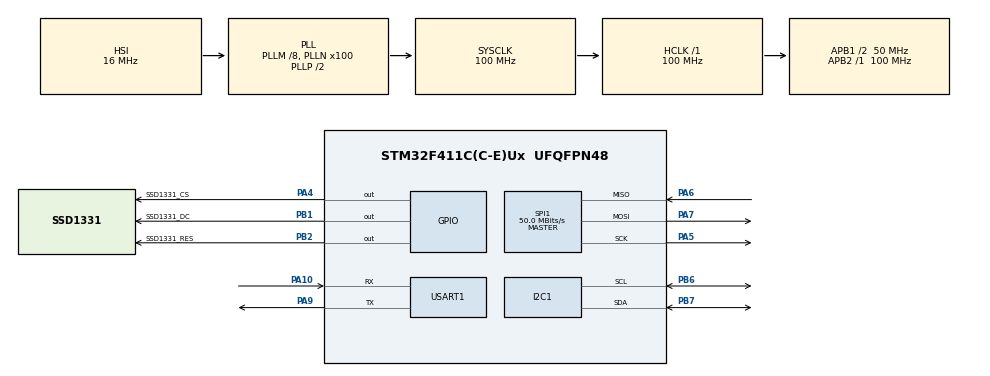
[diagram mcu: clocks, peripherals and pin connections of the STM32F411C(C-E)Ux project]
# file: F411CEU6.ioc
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Dma.Request0=USART1_RX
Dma.USART1_RX.0.Direction=DMA_PERIPH_TO_MEMORY
Dma.USART1_RX.0.FIFOMode=DMA_FIFOMODE_DISABLE
Dma.USART1_RX.0.Instance=DMA2_Stream2
Dma.USART1_RX.0.MemDataAlignment=DMA_MDATAALIGN_BYTE
Dma.USART1_RX.0.MemInc=DMA_MINC_ENABLE
Dma.USART1_RX.0.Mode=DMA_CIRCULAR
Dma.USART1_RX.0.PeriphDataAlignment=DMA_PDATAALIGN_BYTE
Dma.USART1_RX.0.PeriphInc=DMA_PINC_DISABLE
Dma.USART1_RX.0.Priority=DMA_PRIORITY_LOW
FREERTOS.Queues01=uart_tx_queue,4,UART_TX_QUEUE_MSG_t,0,Dynamic,NULL,NULL;display_queue,4,DISPLAY_MSG_t,0,Dynamic,NULL,NULL
FREERTOS.Tasks01=SENSOR_TASK,8,512,SENSOR_TASK_Start,Default,NULL,Dynamic,NULL,NULL;UART_TX_TASK,8,256,UART_TX_TASK_Start,Default,NULL,Dynamic,NULL,NULL;DISPLAY_TASK,40,256,DISPLAY_TASK_Start,Default,NULL,Dynamic,NULL,NULL;UART_RX_TASK,24,512,UART_RX_TASK_Start,Default,NULL,Dynamic,NULL,NULL;FLASH_LOG_TASK,8,256,FLASH_LOG_TASK_Start,Default,NULL,Dynamic,NULL,NULL
Mcu.Family=STM32F4
Mcu.Name=STM32F411C(C-E)Ux
Mcu.Package=UFQFPN48
NVIC.DMA2_Stream2_IRQn=true\:5\:0\:false\:false\:true\:true\:false\:true\:true
NVIC.PriorityGroup=NVIC_PRIORITYGROUP_4
NVIC.RTC_WKUP_IRQn=true\:5\:0\:false\:false\:true\:true\:true\:true\:true
NVIC.USART1_IRQn=true\:5\:0\:false\:false\:true\:true\:true\:true\:true
PA10.Mode=Asynchronous
PA10.Signal=USART1_RX
PA4.GPIO_Label=SSD1331_CS
PA4.GPIO_PuPd=GPIO_PULLUP
PA4.PinState=GPIO_PIN_SET
PA4.Signal=GPIO_Output
PA5.Mode=Full_Duplex_Master
PA5.Signal=SPI1_SCK
PA6.Mode=Full_Duplex_Master
PA6.Signal=SPI1_MISO
PA7.Mode=Full_Duplex_Master
PA7.Signal=SPI1_MOSI
PA9.Mode=Asynchronous
PA9.Signal=USART1_TX
PB1.GPIO_Label=SSD1331_DC
PB1.GPIO_PuPd=GPIO_PULLUP
PB1.PinState=GPIO_PIN_SET
PB1.Signal=GPIO_Output
PB2.GPIO_Label=SSD1331_RES
PB2.GPIO_PuPd=GPIO_PULLUP
PB2.PinState=GPIO_PIN_SET
PB2.Signal=GPIO_Output
PB6.Mode=I2C
PB6.Signal=I2C1_SCL
PB7.Mode=I2C
PB7.Signal=I2C1_SDA
ProjectManager.HeapSize=0x200
ProjectManager.StackSize=0x400
ProjectManager.TargetToolchain=STM32CubeIDE
RCC.48MHZClocksFreq_Value=50000000
RCC.AHBFreq_Value=100000000
RCC.APB1CLKDivider=RCC_HCLK_DIV2
RCC.APB1Freq_Value=50000000
RCC.APB1TimFreq_Value=100000000
RCC.APB2Freq_Value=100000000
RCC.APB2TimFreq_Value=100000000
RCC.CortexFreq_Value=100000000
RCC.HCLKFreq_Value=100000000
RCC.HSE_VALUE=25000000
RCC.HSI_VALUE=16000000
RCC.PLLM=8
RCC.PLLN=100
RCC.RCC_RTC_Clock_Source=RCC_RTCCLKSOURCE_LSI
RCC.RCC_RTC_Clock_SourceVirtual=RCC_RTCCLKSOURCE_LSE
RCC.RCC_RTC_Clock_Source_FROM_HSE=RCC_RTCCLKSOURCE_HSE_DIV25
RCC.SYSCLKFreq_VALUE=100000000
RCC.SYSCLKSource=RCC_SYSCLKSOURCE_PLLCLK
RCC.VCOOutputFreq_Value=200000000
RTC.WakeUpClock=RTC_WAKEUPCLOCK_CK_SPRE_16BITS
RTC.WakeUpCounter=10
SPI1.BaudRatePrescaler=SPI_BAUDRATEPRESCALER_2
SPI1.CalculateBaudRate=50.0 MBits/s
SPI1.Direction=SPI_DIRECTION_2LINES
SPI1.Mode=SPI_MODE_MASTER
SPI1.VirtualType=VM_MASTER
USART1.VirtualMode=VM_ASYNC
VP_FREERTOS_VS_CMSIS_V2.Mode=CMSIS_V2
VP_RTC_VS_RTC_Activate.Mode=RTC_Enabled
VP_RTC_VS_RTC_WakeUp_intern.Mode=WakeUp
board=custom

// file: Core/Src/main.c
/* USER CODE BEGIN Header */
/**
 ******************************************************************************
 * @file           : main.c
 * @brief          : Main program body
 ******************************************************************************
 * @attention
 *
 * Copyright (c) 2026 STMicroelectronics.
 * All rights reserved.
 *
 * This software is licensed under terms that can be found in the LICENSE file
 * in the root directory of this software component.
 * If no LICENSE file comes with this software, it is provided AS-IS.
 *
 ******************************************************************************
 */
/* USER CODE END Header */
#include "main.h"
#include "cmsis_os.h"

/* USER CODE BEGIN Includes */
#include "stdio.h"
#include "string.h"
#include "common.h"
#include "task/display_task.h"
#include "task/sensor_task.h"
#include "task/uart_tx_task.h"
#include "task/uart_rx_task.h"
#include "task/flash_logger_task.h"
/* USER CODE END Includes */

I2C_HandleTypeDef hi2c1;

RTC_HandleTypeDef hrtc;

SPI_HandleTypeDef hspi1;

UART_HandleTypeDef huart1;
DMA_HandleTypeDef hdma_usart1_rx;

/* Definitions for SENSOR_TASK */
osThreadId_t SENSOR_TASKHandle;
const osThreadAttr_t SENSOR_TASK_attributes = {
  .name = "SENSOR_TASK",
  .stack_size = 512 * 4,
  .priority = (osPriority_t) osPriorityLow,
};
/* Definitions for UART_TX_TASK */
osThreadId_t UART_TX_TASKHandle;
const osThreadAttr_t UART_TX_TASK_attributes = {
  .name = "UART_TX_TASK",
  .stack_size = 256 * 4,
  .priority = (osPriority_t) osPriorityLow,
};
/* Definitions for DISPLAY_TASK */
osThreadId_t DISPLAY_TASKHandle;
const osThreadAttr_t DISPLAY_TASK_attributes = {
  .name = "DISPLAY_TASK",
  .stack_size = 256 * 4,
  .priority = (osPriority_t) osPriorityHigh,
};
/* Definitions for UART_RX_TASK */
osThreadId_t UART_RX_TASKHandle;
const osThreadAttr_t UART_RX_TASK_attributes = {
  .name = "UART_RX_TASK",
  .stack_size = 512 * 4,
  .priority = (osPriority_t) osPriorityNormal,
};
/* Definitions for FLASH_LOG_TASK */
osThreadId_t FLASH_LOG_TASKHandle;
const osThreadAttr_t FLASH_LOG_TASK_attributes = {
  .name = "FLASH_LOG_TASK",
  .stack_size = 256 * 4,
  .priority = (osPriority_t) osPriorityLow,
};
/* Definitions for uart_tx_queue */
osMessageQueueId_t uart_tx_queueHandle;
const osMessageQueueAttr_t uart_tx_queue_attributes = {
  .name = "uart_tx_queue"
};
/* Definitions for display_queue */
osMessageQueueId_t display_queueHandle;
const osMessageQueueAttr_t display_queue_attributes = {
  .name = "display_queue"
};

void SystemClock_Config(void);
static void MX_GPIO_Init(void);
static void MX_DMA_Init(void);
static void MX_USART1_UART_Init(void);
static void MX_RTC_Init(void);
static void MX_I2C1_Init(void);
static void MX_SPI1_Init(void);
void SENSOR_TASK_Start(void *argument);
void UART_TX_TASK_Start(void *argument);
void DISPLAY_TASK_Start(void *argument);
void UART_RX_TASK_Start(void *argument);
void FLASH_LOG_TASK_Start(void *argument);

int main(void)
{

  /* MCU Configuration--------------------------------------------------------*/

  /* Reset of all peripherals, Initializes the Flash interface and the Systick. */
  HAL_Init();

  /* Configure the system clock */
  SystemClock_Config();

  /* Initialize all configured peripherals */
  MX_GPIO_Init();
  MX_DMA_Init();
  MX_USART1_UART_Init();
  MX_RTC_Init();
  MX_I2C1_Init();
  MX_SPI1_Init();

  /* Init scheduler */
  osKernelInitialize();

  /* Create the queue(s) */
  /* creation of uart_tx_queue */
  uart_tx_queueHandle = osMessageQueueNew (4, sizeof(UART_TX_QUEUE_MSG_t), &uart_tx_queue_attributes);

  /* creation of display_queue */
  display_queueHandle = osMessageQueueNew (4, sizeof(DISPLAY_MSG_t), &display_queue_attributes);

  /* Create the thread(s) */
  /* creation of SENSOR_TASK */
  SENSOR_TASKHandle = osThreadNew(SENSOR_TASK_Start, NULL, &SENSOR_TASK_attributes);

  /* creation of UART_TX_TASK */
  UART_TX_TASKHandle = osThreadNew(UART_TX_TASK_Start, NULL, &UART_TX_TASK_attributes);

  /* creation of DISPLAY_TASK */
  DISPLAY_TASKHandle = osThreadNew(DISPLAY_TASK_Start, NULL, &DISPLAY_TASK_attributes);

  /* creation of UART_RX_TASK */
  UART_RX_TASKHandle = osThreadNew(UART_RX_TASK_Start, NULL, &UART_RX_TASK_attributes);

  /* creation of FLASH_LOG_TASK */
  FLASH_LOG_TASKHandle = osThreadNew(FLASH_LOG_TASK_Start, NULL, &FLASH_LOG_TASK_attributes);

  /* Start scheduler */
  osKernelStart();

  /* We should never get here as control is now taken by the scheduler */

  /* Infinite loop */
	while (1) {

	}
}

void SystemClock_Config(void)
{
  RCC_OscInitTypeDef RCC_OscInitStruct = {0};
  RCC_ClkInitTypeDef RCC_ClkInitStruct = {0};

  /** Configure the main internal regulator output voltage
  */
  __HAL_RCC_PWR_CLK_ENABLE();
  __HAL_PWR_VOLTAGESCALING_CONFIG(PWR_REGULATOR_VOLTAGE_SCALE1);

  /** Initializes the RCC Oscillators according to the specified parameters
  * in the RCC_OscInitTypeDef structure.
  */
  RCC_OscInitStruct.OscillatorType = RCC_OSCILLATORTYPE_HSI|RCC_OSCILLATORTYPE_LSI;
  RCC_OscInitStruct.HSIState = RCC_HSI_ON;
  RCC_OscInitStruct.HSICalibrationValue = RCC_HSICALIBRATION_DEFAULT;
  RCC_OscInitStruct.LSIState = RCC_LSI_ON;
  RCC_OscInitStruct.PLL.PLLState = RCC_PLL_ON;
  RCC_OscInitStruct.PLL.PLLSource = RCC_PLLSOURCE_HSI;
  RCC_OscInitStruct.PLL.PLLM = 8;
  RCC_OscInitStruct.PLL.PLLN = 100;
  RCC_OscInitStruct.PLL.PLLP = RCC_PLLP_DIV2;
  RCC_OscInitStruct.PLL.PLLQ = 4;
  if (HAL_RCC_OscConfig(&RCC_OscInitStruct) != HAL_OK)
  {
    Error_Handler();
  }

  /** Initializes the CPU, AHB and APB buses clocks
  */
  RCC_ClkInitStruct.ClockType = RCC_CLOCKTYPE_HCLK|RCC_CLOCKTYPE_SYSCLK
                              |RCC_CLOCKTYPE_PCLK1|RCC_CLOCKTYPE_PCLK2;
  RCC_ClkInitStruct.SYSCLKSource = RCC_SYSCLKSOURCE_PLLCLK;
  RCC_ClkInitStruct.AHBCLKDivider = RCC_SYSCLK_DIV1;
  RCC_ClkInitStruct.APB1CLKDivider = RCC_HCLK_DIV2;
  RCC_ClkInitStruct.APB2CLKDivider = RCC_HCLK_DIV1;

  if (HAL_RCC_ClockConfig(&RCC_ClkInitStruct, FLASH_LATENCY_3) != HAL_OK)
  {
    Error_Handler();
  }
}

static void MX_I2C1_Init(void)
{

  hi2c1.Instance = I2C1;
  hi2c1.Init.ClockSpeed = 100000;
  hi2c1.Init.DutyCycle = I2C_DUTYCYCLE_2;
  hi2c1.Init.OwnAddress1 = 0;
  hi2c1.Init.AddressingMode = I2C_ADDRESSINGMODE_7BIT;
  hi2c1.Init.DualAddressMode = I2C_DUALADDRESS_DISABLE;
  hi2c1.Init.OwnAddress2 = 0;
  hi2c1.Init.GeneralCallMode = I2C_GENERALCALL_DISABLE;
  hi2c1.Init.NoStretchMode = I2C_NOSTRETCH_DISABLE;
  if (HAL_I2C_Init(&hi2c1) != HAL_OK)
  {
    Error_Handler();
  }

}

static void MX_RTC_Init(void)
{

  RTC_TimeTypeDef sTime = {0};
  RTC_DateTypeDef sDate = {0};

  /** Initialize RTC Only
  */
  hrtc.Instance = RTC;
  hrtc.Init.HourFormat = RTC_HOURFORMAT_24;
  hrtc.Init.AsynchPrediv = 127;
  hrtc.Init.SynchPrediv = 255;
  hrtc.Init.OutPut = RTC_OUTPUT_DISABLE;
  hrtc.Init.OutPutPolarity = RTC_OUTPUT_POLARITY_HIGH;
  hrtc.Init.OutPutType = RTC_OUTPUT_TYPE_OPENDRAIN;
  if (HAL_RTC_Init(&hrtc) != HAL_OK)
  {
    Error_Handler();
  }

  /** Initialize RTC and set the Time and Date
  */
  sTime.Hours = 0x0;
  sTime.Minutes = 0x0;
  sTime.Seconds = 0x0;
  sTime.DayLightSaving = RTC_DAYLIGHTSAVING_NONE;
  sTime.StoreOperation = RTC_STOREOPERATION_RESET;
  if (HAL_RTC_SetTime(&hrtc, &sTime, RTC_FORMAT_BCD) != HAL_OK)
  {
    Error_Handler();
  }
  sDate.WeekDay = RTC_WEEKDAY_MONDAY;
  sDate.Month = RTC_MONTH_JANUARY;
  sDate.Date = 0x1;
  sDate.Year = 0x0;

  if (HAL_RTC_SetDate(&hrtc, &sDate, RTC_FORMAT_BCD) != HAL_OK)
  {
    Error_Handler();
  }

  /** Enable the WakeUp
  */
  if (HAL_RTCEx_SetWakeUpTimer_IT(&hrtc, 10, RTC_WAKEUPCLOCK_CK_SPRE_16BITS) != HAL_OK)
  {
    Error_Handler();
  }

}

static void MX_SPI1_Init(void)
{

  /* SPI1 parameter configuration*/
  hspi1.Instance = SPI1;
  hspi1.Init.Mode = SPI_MODE_MASTER;
  hspi1.Init.Direction = SPI_DIRECTION_2LINES;
  hspi1.Init.DataSize = SPI_DATASIZE_8BIT;
  hspi1.Init.CLKPolarity = SPI_POLARITY_LOW;
  hspi1.Init.CLKPhase = SPI_PHASE_1EDGE;
  hspi1.Init.NSS = SPI_NSS_SOFT;
  hspi1.Init.BaudRatePrescaler = SPI_BAUDRATEPRESCALER_2;
  hspi1.Init.FirstBit = SPI_FIRSTBIT_MSB;
  hspi1.Init.TIMode = SPI_TIMODE_DISABLE;
  hspi1.Init.CRCCalculation = SPI_CRCCALCULATION_DISABLE;
  hspi1.Init.CRCPolynomial = 10;
  if (HAL_SPI_Init(&hspi1) != HAL_OK)
  {
    Error_Handler();
  }

}

static void MX_USART1_UART_Init(void)
{

  huart1.Instance = USART1;
  huart1.Init.BaudRate = 115200;
  huart1.Init.WordLength = UART_WORDLENGTH_8B;
  huart1.Init.StopBits = UART_STOPBITS_1;
  huart1.Init.Parity = UART_PARITY_NONE;
  huart1.Init.Mode = UART_MODE_TX_RX;
  huart1.Init.HwFlowCtl = UART_HWCONTROL_NONE;
  huart1.Init.OverSampling = UART_OVERSAMPLING_16;
  if (HAL_UART_Init(&huart1) != HAL_OK)
  {
    Error_Handler();
  }

}

static void MX_DMA_Init(void)
{

  /* DMA controller clock enable */
  __HAL_RCC_DMA2_CLK_ENABLE();

  /* DMA interrupt init */
  /* DMA2_Stream2_IRQn interrupt configuration */
  HAL_NVIC_SetPriority(DMA2_Stream2_IRQn, 5, 0);
  HAL_NVIC_EnableIRQ(DMA2_Stream2_IRQn);

}

static void MX_GPIO_Init(void)
{
  GPIO_InitTypeDef GPIO_InitStruct = {0};

  /* GPIO Ports Clock Enable */
  __HAL_RCC_GPIOA_CLK_ENABLE();
  __HAL_RCC_GPIOB_CLK_ENABLE();

  /*Configure GPIO pin Output Level */
  HAL_GPIO_WritePin(SSD1331_CS_GPIO_Port, SSD1331_CS_Pin, GPIO_PIN_SET);

  /*Configure GPIO pin Output Level */
  HAL_GPIO_WritePin(GPIOB, SSD1331_DC_Pin|SSD1331_RES_Pin, GPIO_PIN_SET);

  /*Configure GPIO pin : SSD1331_CS_Pin */
  GPIO_InitStruct.Pin = SSD1331_CS_Pin;
  GPIO_InitStruct.Mode = GPIO_MODE_OUTPUT_PP;
  GPIO_InitStruct.Pull = GPIO_PULLUP;
  GPIO_InitStruct.Speed = GPIO_SPEED_FREQ_LOW;
  HAL_GPIO_Init(SSD1331_CS_GPIO_Port, &GPIO_InitStruct);

  /*Configure GPIO pins : SSD1331_DC_Pin SSD1331_RES_Pin */
  GPIO_InitStruct.Pin = SSD1331_DC_Pin|SSD1331_RES_Pin;
  GPIO_InitStruct.Mode = GPIO_MODE_OUTPUT_PP;
  GPIO_InitStruct.Pull = GPIO_PULLUP;
  GPIO_InitStruct.Speed = GPIO_SPEED_FREQ_LOW;
  HAL_GPIO_Init(GPIOB, &GPIO_InitStruct);

}

void SENSOR_TASK_Start(void *argument)
{
  /* USER CODE BEGIN 5 */
  /* Infinite loop */
  UAL_SENSOR_TASK_Start(argument);
  /* USER CODE END 5 */
}

void UART_TX_TASK_Start(void *argument)
{
  /* USER CODE BEGIN UART_TX_TASK_Start */
  /* Infinite loop */
  UAL_UART_TX_TASK_Start(argument);
  /* USER CODE END UART_TX_TASK_Start */
}

void DISPLAY_TASK_Start(void *argument)
{
  /* USER CODE BEGIN DISPLAY_TASK_Start */
  /* Infinite loop */
  UAL_DISPLAY_TASK_Start(argument);
  /* USER CODE END DISPLAY_TASK_Start */
}

void UART_RX_TASK_Start(void *argument)
{
  /* USER CODE BEGIN UART_RX_TASK_Start */
  /* Infinite loop */
  UAL_UART_RX_TASK_Start(argument);
  /* USER CODE END UART_RX_TASK_Start */
}

void FLASH_LOG_TASK_Start(void *argument)
{
  /* USER CODE BEGIN FLASH_LOG_TASK_Start */
  /* Infinite loop */
  UAL_FLASH_LOGGER_TASK_Start(argument);
  /* USER CODE END FLASH_LOG_TASK_Start */
}

void Error_Handler(void)
{
	__disable_irq();
	while (1) {
	}
}
